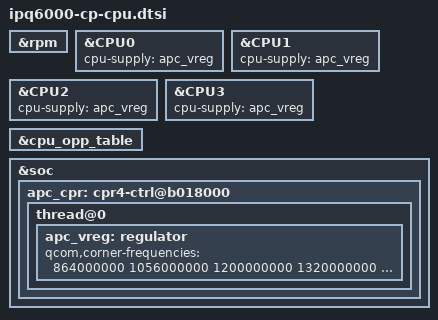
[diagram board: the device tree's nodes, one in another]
// SPDX-License-Identifier: GPL-2.0-only

#include "ipq6018-cpr-regulator.dtsi"

&rpm {
	status = "okay";
};

&CPU0 {
	cpu-supply = <&apc_vreg>;
};

&CPU1 {
	cpu-supply = <&apc_vreg>;
};

&CPU2 {
	cpu-supply = <&apc_vreg>;
};

&CPU3 {
	cpu-supply = <&apc_vreg>;
};

&cpu_opp_table {
	/delete-node/ opp-1608000000;
	/delete-node/ opp-1800000000;
};

&soc {
	apc_cpr: cpr4-ctrl@b018000 {
		thread@0 {
			apc_vreg: regulator {
				qcom,corner-frequencies = <864000000 1056000000 1200000000 1320000000 1440000000 1512000000>;
			};
		};
	};
};
